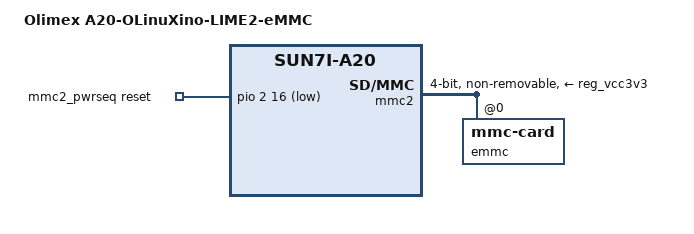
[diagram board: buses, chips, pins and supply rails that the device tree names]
 /*
 * Copyright 2015 - Ultimaker B.V.
 * Author Olliver Schinagl <oliver@schinagl.nl>
 *
 * This file is dual-licensed: you can use it either under the terms
 * of the GPL or the X11 license, at your option. Note that this dual
 * licensing only applies to this file, and not this project as a
 * whole.
 *
 *  a) This file is free software; you can redistribute it and/or
 *     modify it under the terms of the GNU General Public License as
 *     published by the Free Software Foundation; either version 2 of the
 *     License, or (at your option) any later version.
 *
 *     This file is distributed in the hope that it will be useful,
 *     but WITHOUT ANY WARRANTY; without even the implied warranty of
 *     MERCHANTABILITY or FITNESS FOR A PARTICULAR PURPOSE.  See the
 *     GNU General Public License for more details.
 *
 * Or, alternatively,
 *
 *  b) Permission is hereby granted, free of charge, to any person
 *     obtaining a copy of this software and associated documentation
 *     files (the "Software"), to deal in the Software without
 *     restriction, including without limitation the rights to use,
 *     copy, modify, merge, publish, distribute, sublicense, and/or
 *     sell copies of the Software, and to permit persons to whom the
 *     Software is furnished to do so, subject to the following
 *     conditions:
 *
 *     The above copyright notice and this permission notice shall be
 *     included in all copies or substantial portions of the Software.
 *
 *     THE SOFTWARE IS PROVIDED "AS IS", WITHOUT WARRANTY OF ANY KIND,
 *     EXPRESS OR IMPLIED, INCLUDING BUT NOT LIMITED TO THE WARRANTIES
 *     OF MERCHANTABILITY, FITNESS FOR A PARTICULAR PURPOSE AND
 *     NONINFRINGEMENT. IN NO EVENT SHALL THE AUTHORS OR COPYRIGHT
 *     HOLDERS BE LIABLE FOR ANY CLAIM, DAMAGES OR OTHER LIABILITY,
 *     WHETHER IN AN ACTION OF CONTRACT, TORT OR OTHERWISE, ARISING
 *     FROM, OUT OF OR IN CONNECTION WITH THE SOFTWARE OR THE USE OR
 *     OTHER DEALINGS IN THE SOFTWARE.
 */

#include "sun7i-a20-olinuxino-lime2.dts"

/ {
	model = "Olimex A20-OLinuXino-LIME2-eMMC";
	compatible = "olimex,a20-olinuxino-lime2-emmc", "allwinner,sun7i-a20";

	mmc2_pwrseq: pwrseq {
		pinctrl-0 = <&mmc2_pins_nrst>;
		pinctrl-names = "default";
		compatible = "mmc-pwrseq-emmc";
		reset-gpios = <&pio 2 16 GPIO_ACTIVE_LOW>;
	};
};

&pio {
	mmc2_pins_nrst: mmc2-rst-pin {
		pins = "PC16";
		function = "gpio_out";
	};
};

&mmc2 {
	pinctrl-names = "default";
	pinctrl-0 = <&mmc2_pins_a>;
	vmmc-supply = <&reg_vcc3v3>;
	vqmmc-supply = <&reg_vcc3v3>;
	bus-width = <4>;
	non-removable;
	mmc-pwrseq = <&mmc2_pwrseq>;
	status = "okay";

	emmc: emmc@0 {
		reg = <0>;
		compatible = "mmc-card";
		broken-hpi;
	};
};
